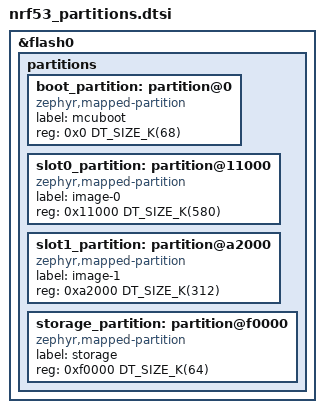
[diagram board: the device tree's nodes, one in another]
/*
 * Copyright (c) 2026 Nordic Semiconductor ASA
 *
 * SPDX-License-Identifier: LicenseRef-Nordic-5-Clause
 */

/delete-node/ &boot_partition;
/delete-node/ &slot0_partition;
/delete-node/ &slot1_partition;
/delete-node/ &storage_partition;

&flash0 {
	partitions {
		ranges;
		#address-cells = <1>;
		#size-cells = <1>;

		boot_partition: partition@0 {
			compatible = "zephyr,mapped-partition";
			label = "mcuboot";
			reg = <0x0 DT_SIZE_K(68)>;
		};

		slot0_partition: partition@11000 {
			compatible = "zephyr,mapped-partition";
			label = "image-0";
			reg = <0x11000 DT_SIZE_K(580)>;
		};

		slot1_partition: partition@a2000 {
			compatible = "zephyr,mapped-partition";
			label = "image-1";
			reg = <0xa2000 DT_SIZE_K(312)>;
		};

		storage_partition: partition@f0000 {
			compatible = "zephyr,mapped-partition";
			label = "storage";
			reg = <0xf0000 DT_SIZE_K(64)>;
		};
	};
};
